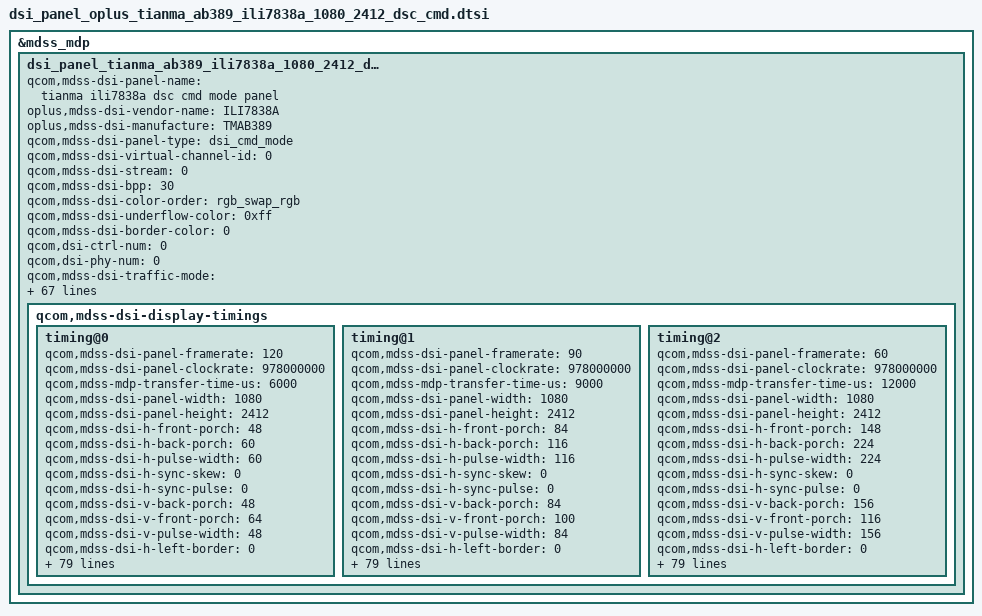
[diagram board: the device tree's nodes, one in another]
&mdss_mdp {
	dsi_panel_tianma_ab389_ili7838a_1080_2412_dsc_cmd: qcom,mdss_dsi_panel_tianma_ab389_ili7838a_1080_2412_dsc_cmd {
		qcom,mdss-dsi-panel-name = "tianma ili7838a dsc cmd mode panel";
		oplus,mdss-dsi-vendor-name = "ILI7838A";
		oplus,mdss-dsi-manufacture = "TMAB389";
		qcom,mdss-dsi-panel-type = "dsi_cmd_mode";
		qcom,mdss-dsi-virtual-channel-id = <0>;
		qcom,mdss-dsi-stream = <0>;
		qcom,mdss-dsi-bpp = <30>;
		qcom,mdss-dsi-color-order = "rgb_swap_rgb";
		qcom,mdss-dsi-underflow-color = <0xff>;
		qcom,mdss-dsi-border-color = <0>;
		qcom,dsi-ctrl-num = <0>;
		qcom,dsi-phy-num = <0>;
		qcom,mdss-dsi-traffic-mode = "non_burst_sync_event";
		qcom,mdss-dsi-lane-map = "lane_map_0123";
		qcom,mdss-dsi-bllp-eof-power-mode;
		qcom,mdss-dsi-bllp-power-mode;
		qcom,mdss-dsi-lane-0-state;
		qcom,mdss-dsi-lane-1-state;
		qcom,mdss-dsi-lane-2-state;
		qcom,mdss-dsi-lane-3-state;
		qcom,mdss-dsi-dma-trigger = "trigger_sw";
		qcom,mdss-dsi-mdp-trigger = "none";
		qcom,mdss-dsi-reset-sequence = <1 10>, <0 10>, <1 10>;

		qcom,mdss-dsi-te-pin-select = <1>;
		qcom,mdss-dsi-te-dcs-command = <1>;
		qcom,mdss-dsi-te-check-enable;
		qcom,mdss-dsi-te-using-te-pin;
		qcom,mdss-dsi-lp11-init;
		qcom,mdss-dsi-wr-mem-start = <0x2c>;
		qcom,mdss-dsi-wr-mem-continue = <0x3c>;
		qcom,mdss-dsi-panel-hdr-enabled;
		qcom,mdss-dsi-panel-hdr-color-primaries = <15635 16450 34000 16000 13250 34500 7500 3000>;
		qcom,mdss-dsi-panel-peak-brightness = <5400000>;
		qcom,mdss-dsi-panel-blackness-level = <2000>;
		qcom,mdss-pan-physical-width-dimension = <70>;
		qcom,mdss-pan-physical-height-dimension = <155>;
		qcom,esd-check-enabled;
		qcom,mdss-dsi-panel-status-check-mode = "reg_read";
		qcom,mdss-dsi-panel-status-command = [06 01 00 01 00 00 01 0A];
		qcom,mdss-dsi-panel-status-command-state = "dsi_lp_mode";
		qcom,mdss-dsi-panel-status-value = <0x9C>;
		qcom,mdss-dsi-panel-status-read-length = <1>;
		qcom,dynamic-mode-switch-enabled;
		qcom,dynamic-mode-switch-type = "dynamic-resolution-switch-immediate";
		qcom,mdss-dsi-display-timings {
			timing@0 {
				qcom,mdss-dsi-panel-framerate = <120>;
				qcom,mdss-dsi-panel-clockrate = <978000000>;
				qcom,mdss-mdp-transfer-time-us = <6000>;
				qcom,mdss-dsi-panel-width = <1080>;
				qcom,mdss-dsi-panel-height = <2412>;
				qcom,mdss-dsi-h-front-porch = <48>;
				qcom,mdss-dsi-h-back-porch = <60>;
				qcom,mdss-dsi-h-pulse-width = <60>;
				qcom,mdss-dsi-h-sync-skew = <0>;
				qcom,mdss-dsi-h-sync-pulse = <0>;
				qcom,mdss-dsi-v-back-porch = <48>;
				qcom,mdss-dsi-v-front-porch = <64>;
				qcom,mdss-dsi-v-pulse-width = <48>;
				qcom,mdss-dsi-h-left-border = <0>;
				qcom,mdss-dsi-h-right-border = <0>;
				qcom,mdss-dsi-v-top-border = <0>;
				qcom,mdss-dsi-v-bottom-border = <0>;
				qcom,mdss-dsi-panel-jitter = <0x4 0x1>;

				/* ofp config */
				oplus,ofp-need-to-separate-backlight;
				oplus,ofp-hbm-on-period = <2>;

				qcom,mdss-dsi-timing-switch-command = [
					//120HZ
					39 00 00 40 00 00 04 FF 78 38 02
					39 00 00 40 00 00 02 38 11
					39 00 00 00 00 00 04 FF 78 38 00
				];
				qcom,mdss-dsi-on-command = [
					//APL Peak Luminance ON
					39 00 00 40 00 00 04 FF 78 38 0B
					39 00 00 40 00 00 02 17 F3
					39 00 00 40 00 00 02 18 F3
					39 00 00 40 00 00 02 19 F3
					39 00 00 40 00 00 02 1A F3
					39 00 00 40 00 00 02 1B F3
					39 00 00 40 00 00 02 1C F3
					39 00 00 40 00 00 02 1D F3
					39 00 00 40 00 00 04 FF 78 38 0A
					39 00 00 40 00 00 02 37 4F
					39 00 00 40 00 00 02 38 70
					39 00 00 40 00 00 04 FF 78 38 00
					39 00 00 00 00 00 02 55 03
					//R Corner Control off
					39 00 00 40 00 00 04 FF 78 38 17
					39 00 00 00 00 00 02 20 00
					//NVM Reload
					39 00 00 40 00 00 04 FF 78 38 08
					39 00 00 00 00 00 02 45 4C
					//DSC 10Bit
					39 00 00 40 00 00 04 FF 78 38 07
					39 00 00 40 00 00 02 29 01
					39 00 00 00 00 00 64 20 00 00 00
					00 00 11 00 00 ab 30 a0 09 6c 04
					38 00 0c 02 1c 02 a3 01 9a 01 d8
					00 19 01 03 00 0a 00 0c 08 bb 0a
					5f 16 00 10 ec 07 10 20 00 06 0f
					0f 33 0e 1c 2a 38 46 54 62 69 70
					77 79 7b 7d 7e 01 c2 22 00 2a 40
					32 be 3a fc 3a fa 3a f8 3b 38 3b
					78 3b 76 4b b6 4b b6 4b f4 5b f4
					7c 34 00 00 00 00 00 00
					//Frequence Transition
					39 00 00 40 00 00 04 FF 78 38 02
					39 00 00 00 00 00 02 38 11
					//IR IP ON
					39 00 00 40 00 00 04 FF 78 38 00
					39 00 00 00 00 00 02 95 10
					//TE ON
					39 00 00 40 00 00 04 FF 78 38 00
					39 00 00 00 00 00 02 35 00
					//Dimming Setting
					39 00 00 40 00 00 02 53 20
					39 00 00 00 00 00 03 51 00 00
					//Sleep out
					05 00 00 00 78 00 01 11
					//ESD Check
					39 00 00 40 00 00 04 FF 78 38 08
					39 00 00 40 00 00 02 57 25
					39 00 00 40 00 00 04 FF 78 38 06
					39 00 00 40 0A 00 02 C6 01
					39 00 00 00 00 00 04 FF 78 38 00
					//Display on
					05 00 00 00 46 00 01 29
				];
				qcom,mdss-dsi-off-command= [
					05 00 00 40 0B 00 01 28
					05 00 00 00 79 00 01 10];
				qcom,mdss-dsi-post-on-backlight = [
					/* Display On */
					05 00 00 00 00 00 01 29
				];
				qcom,mdss-dsi-panel-info-switch-page-command = [
					/*read panel info switch page 0f*/
					39 00 00 00 00 00 04 FF 78 38 0F
				];
				qcom,mdss-dsi-default-switch-page-command = [
					/*switch default page*/
					39 00 00 00 00 00 04 FF 78 38 00
				];

				//qcom,mdss-dsi-seed-off-command = [

				//];
				//qcom,mdss-dsi-seed-3-command = [

				//];
				//qcom,mdss-dsi-seed-2-command = [

				//];
				//qcom,mdss-dsi-seed-1-command = [

				//];
				//qcom,mdss-dsi-seed-0-command = [

				//];
				qcom,mdss-dsi-hbm-enter-switch-command = [
					39 00 00 00 00 00 03 51 0D BB
				];
				qcom,mdss-dsi-hbm-exit-switch-command = [
					39 00 00 00 00 00 03 51 0D BB
				];

				qcom,mdss-dsi-hbm-on-command = [
					/* HBM Mode ON */
					39 00 00 00 00 00 03 51 0F FF
				];
				qcom,mdss-dsi-hbm-off-command = [
					/* HBM Mode OFF */
					39 00 00 00 00 00 03 51 0D BB
				];
				qcom,mdss-dsi-lp1-command = [
					/* AOD Mode ON */
					39 00 00 40 00 00 04 FF 78 38 00
					05 00 00 40 00 00 01 39
					39 00 00 40 00 00 04 FF 78 38 0C
					15 00 00 40 00 00 02 BE 01
					39 00 00 00 00 00 04 FF 78 38 00
				];
				qcom,mdss-dsi-nolp-command = [
					/* AOD Mode OFF */
					39 00 00 40 00 00 04 FF 78 38 00
					05 00 00 40 00 00 01 38
					39 00 00 00 00 00 03 51 00 00
				];
				qcom,mdss-dsi-aod-high-mode-command = [
					/* AOD High Mode, 50nit */
					39 00 00 40 00 00 04 FF 78 38 0C
					15 00 00 40 00 00 02 BE 01
					39 00 00 00 00 00 04 FF 78 38 00
				];
				qcom,mdss-dsi-aod-low-mode-command = [
					/* AOD Low Mode 10nit */
					39 00 00 40 00 00 04 FF 78 38 0C
					15 00 00 40 00 00 02 BE 00
					39 00 00 00 00 00 04 FF 78 38 00
				];

				qcom,mdss-dsi-loading-effect-1-command = [
				];
				qcom,mdss-dsi-loading-effect-2-command = [
				];
				qcom,mdss-dsi-loading-effect-off-command = [
				];

				qcom,mdss-dsi-osc-clk-mode0-command = [

				];
				qcom,mdss-dsi-osc-clk-mode1-command = [

				];
				qcom,mdss-dsi-timing-switch-command-state = "dsi_lp_mode";
				qcom,mdss-dsi-on-command-state = "dsi_lp_mode";
				qcom,mdss-dsi-off-command-state = "dsi_lp_mode";
				qcom,mdss-dsi-panel-info-switch-page-command-state = "dsi_lp_mode";
				qcom,mdss-dsi-default-switch-page-command-state = "dsi_lp_mode";
				qcom,mdss-dsi-hbm-on-command-state = "dsi_lp_mode";
				qcom,mdss-dsi-hbm-off-command-state = "dsi_lp_mode";
				qcom,mdss-dsi-lp1-command-state = "dsi_lp_mode";
				qcom,mdss-dsi-nolp-command-state = "dsi_lp_mode";
				qcom,mdss-dsi-aod-high-mode-command-state = "dsi_lp_mode";
				qcom,mdss-dsi-aod-low-mode-command-state = "dsi_lp_mode";
				qcom,mdss-dsi-loading-effect-1-command-state = "dsi_lp_mode";
				qcom,mdss-dsi-loading-effect-2-command-state = "dsi_lp_mode";
				qcom,mdss-dsi-loading-effect-off-command-state = "dsi_lp_mode";
				qcom,mdss-dsi-osc-clk-mode0-command-state = "dsi_lp_mode";
				qcom,mdss-dsi-osc-clk-mode1-command-state = "dsi_lp_mode";
				//qcom,mdss-dsi-seed-0-command-state = "dsi_lp_mode";
				//qcom,mdss-dsi-seed-1-command-state = "dsi_lp_mode";
				//qcom,mdss-dsi-seed-2-command-state = "dsi_lp_mode";
				//qcom,mdss-dsi-seed-3-command-state = "dsi_lp_mode";
				//qcom,mdss-dsi-seed-off-command-state = "dsi_lp_mode";
				qcom,compression-mode = "dsc";
				qcom,mdss-dsc-slice-height = <12>;
				qcom,mdss-dsc-slice-width = <540>;
				qcom,mdss-dsc-slice-per-pkt = <2>;
				qcom,mdss-dsc-bit-per-component = <10>;
				qcom,mdss-dsc-bit-per-pixel = <10>;
				qcom,mdss-dsc-block-prediction-enable;
				qcom,mdss-dsc-version = <0x12>;
			};
			timing@1 {
				qcom,mdss-dsi-panel-framerate = <90>;
				qcom,mdss-dsi-panel-clockrate = <978000000>;
				qcom,mdss-mdp-transfer-time-us = <9000>;
				qcom,mdss-dsi-panel-width = <1080>;
				qcom,mdss-dsi-panel-height = <2412>;
				qcom,mdss-dsi-h-front-porch = <84>;
				qcom,mdss-dsi-h-back-porch = <116>;
				qcom,mdss-dsi-h-pulse-width = <116>;
				qcom,mdss-dsi-h-sync-skew = <0>;
				qcom,mdss-dsi-h-sync-pulse = <0>;
				qcom,mdss-dsi-v-back-porch = <84>;
				qcom,mdss-dsi-v-front-porch = <100>;
				qcom,mdss-dsi-v-pulse-width = <84>;
				qcom,mdss-dsi-h-left-border = <0>;
				qcom,mdss-dsi-h-right-border = <0>;
				qcom,mdss-dsi-v-top-border = <0>;
				qcom,mdss-dsi-v-bottom-border = <0>;
				qcom,mdss-dsi-panel-jitter = <0x4 0x1>;

				/* ofp config */
				oplus,ofp-need-to-separate-backlight;
				oplus,ofp-hbm-on-period = <2>;

				qcom,mdss-dsi-timing-switch-command = [
					//90HZ
					39 00 00 40 00 00 04 FF 78 38 02
					39 00 00 40 00 00 02 38 12
					39 00 00 00 00 00 04 FF 78 38 00
				];
				qcom,mdss-dsi-on-command = [
					//APL Peak Luminance ON
					39 00 00 40 00 00 04 FF 78 38 0B
					39 00 00 40 00 00 02 17 F3
					39 00 00 40 00 00 02 18 F3
					39 00 00 40 00 00 02 19 F3
					39 00 00 40 00 00 02 1A F3
					39 00 00 40 00 00 02 1B F3
					39 00 00 40 00 00 02 1C F3
					39 00 00 40 00 00 02 1D F3
					39 00 00 40 00 00 04 FF 78 38 0A
					39 00 00 40 00 00 02 37 4F
					39 00 00 40 00 00 02 38 70
					39 00 00 40 00 00 04 FF 78 38 00
					39 00 00 00 00 00 02 55 03
					//R Corner Control off
					39 00 00 40 00 00 04 FF 78 38 17
					39 00 00 00 00 00 02 20 00
					//NVM Reload
					39 00 00 40 00 00 04 FF 78 38 08
					39 00 00 00 00 00 02 45 4C
					//DSC 10Bit
					39 00 00 40 00 00 04 FF 78 38 07
					39 00 00 40 00 00 02 29 01
					39 00 00 00 00 00 64 20 00 00 00
					00 00 11 00 00 ab 30 a0 09 6c 04
					38 00 0c 02 1c 02 a3 01 9a 01 d8
					00 19 01 03 00 0a 00 0c 08 bb 0a
					5f 16 00 10 ec 07 10 20 00 06 0f
					0f 33 0e 1c 2a 38 46 54 62 69 70
					77 79 7b 7d 7e 01 c2 22 00 2a 40
					32 be 3a fc 3a fa 3a f8 3b 38 3b
					78 3b 76 4b b6 4b b6 4b f4 5b f4
					7c 34 00 00 00 00 00 00
					//Frequence Transition
					39 00 00 40 00 00 04 FF 78 38 02
					39 00 00 00 00 00 02 38 12
					//IR IP ON
					39 00 00 40 00 00 04 FF 78 38 00
					39 00 00 00 00 00 02 95 10
					//TE ON
					39 00 00 40 00 00 04 FF 78 38 00
					39 00 00 00 00 00 02 35 00
					//Dimming Setting
					39 00 00 40 00 00 02 53 20
					39 00 00 00 00 00 03 51 00 00
					//Sleep out
					05 00 00 00 78 00 01 11
					//ESD Check
					39 00 00 40 00 00 04 FF 78 38 08
					39 00 00 40 00 00 02 57 25
					39 00 00 40 00 00 04 FF 78 38 06
					39 00 00 40 0A 00 02 C6 01
					39 00 00 00 00 00 04 FF 78 38 00
					//Display on
					05 00 00 00 46 00 01 29
				];
				qcom,mdss-dsi-off-command= [
					05 00 00 40 0B 00 01 28
					05 00 00 00 79 00 01 10];
				qcom,mdss-dsi-post-on-backlight = [
					/* Display On */
					05 00 00 00 00 00 01 29
				];
				qcom,mdss-dsi-panel-info-switch-page-command = [
					/*read panel info switch page 0f*/
					39 00 00 00 00 00 04 FF 78 38 0F
				];
				qcom,mdss-dsi-default-switch-page-command = [
					/*switch default page*/
					39 00 00 00 00 00 04 FF 78 38 00
				];

				qcom,mdss-dsi-hbm-enter-switch-command = [
					39 00 00 00 00 00 03 51 0D BB
				];
				qcom,mdss-dsi-hbm-exit-switch-command = [
					39 00 00 00 00 00 03 51 0D BB
				];

				qcom,mdss-dsi-hbm-on-command = [
					/* HBM Mode ON */
					39 00 00 00 00 00 03 51 0F FF
				];
				qcom,mdss-dsi-hbm-off-command = [
					/* HBM Mode OFF */
					39 00 00 00 00 00 03 51 0D BB
				];
				qcom,mdss-dsi-lp1-command = [
					/* AOD Mode ON */
					39 00 00 40 00 00 04 FF 78 38 00
					05 00 00 40 00 00 01 39
					39 00 00 40 00 00 04 FF 78 38 0C
					15 00 00 40 00 00 02 BE 01
					39 00 00 00 00 00 04 FF 78 38 00
				];
				qcom,mdss-dsi-nolp-command = [
					/* AOD Mode OFF */
					39 00 00 40 00 00 04 FF 78 38 00
					05 00 00 40 00 00 01 38
					39 00 00 00 00 00 03 51 00 00
				];
				qcom,mdss-dsi-aod-high-mode-command = [
					/* AOD High Mode, 50nit */
					39 00 00 40 00 00 04 FF 78 38 0C
					15 00 00 40 00 00 02 BE 01
					39 00 00 00 00 00 04 FF 78 38 00
				];
				qcom,mdss-dsi-aod-low-mode-command = [
					/* AOD Low Mode 10nit */
					39 00 00 40 00 00 04 FF 78 38 0C
					15 00 00 40 00 00 02 BE 00
					39 00 00 00 00 00 04 FF 78 38 00
				];

				qcom,mdss-dsi-loading-effect-1-command = [
				];
				qcom,mdss-dsi-loading-effect-2-command = [
				];
				qcom,mdss-dsi-loading-effect-off-command = [
				];

				qcom,mdss-dsi-osc-clk-mode0-command = [

				];
				qcom,mdss-dsi-osc-clk-mode1-command = [

				];
				qcom,mdss-dsi-timing-switch-command-state = "dsi_lp_mode";
				qcom,mdss-dsi-on-command-state = "dsi_lp_mode";
				qcom,mdss-dsi-off-command-state = "dsi_lp_mode";
				qcom,mdss-dsi-panel-info-switch-page-command-state = "dsi_lp_mode";
				qcom,mdss-dsi-default-switch-page-command-state = "dsi_lp_mode";
				qcom,mdss-dsi-hbm-on-command-state = "dsi_lp_mode";
				qcom,mdss-dsi-hbm-off-command-state = "dsi_lp_mode";
				qcom,mdss-dsi-lp1-command-state = "dsi_lp_mode";
				qcom,mdss-dsi-nolp-command-state = "dsi_lp_mode";
				qcom,mdss-dsi-aod-high-mode-command-state = "dsi_lp_mode";
				qcom,mdss-dsi-aod-low-mode-command-state = "dsi_lp_mode";
				qcom,mdss-dsi-loading-effect-1-command-state = "dsi_lp_mode";
				qcom,mdss-dsi-loading-effect-2-command-state = "dsi_lp_mode";
				qcom,mdss-dsi-loading-effect-off-command-state = "dsi_lp_mode";
				qcom,mdss-dsi-osc-clk-mode0-command-state = "dsi_lp_mode";
				qcom,mdss-dsi-osc-clk-mode1-command-state = "dsi_lp_mode";
				qcom,compression-mode = "dsc";
				qcom,mdss-dsc-slice-height = <12>;
				qcom,mdss-dsc-slice-width = <540>;
				qcom,mdss-dsc-slice-per-pkt = <2>;
				qcom,mdss-dsc-bit-per-component = <10>;
				qcom,mdss-dsc-bit-per-pixel = <10>;
				qcom,mdss-dsc-block-prediction-enable;
				qcom,mdss-dsc-version = <0x12>;
			};
			timing@2 {
				qcom,mdss-dsi-panel-framerate = <60>;
				qcom,mdss-dsi-panel-clockrate = <978000000>;
				qcom,mdss-mdp-transfer-time-us = <12000>;
				qcom,mdss-dsi-panel-width = <1080>;
				qcom,mdss-dsi-panel-height = <2412>;
				qcom,mdss-dsi-h-front-porch = <148>;
				qcom,mdss-dsi-h-back-porch = <224>;
				qcom,mdss-dsi-h-pulse-width = <224>;
				qcom,mdss-dsi-h-sync-skew = <0>;
				qcom,mdss-dsi-h-sync-pulse = <0>;
				qcom,mdss-dsi-v-back-porch = <156>;
				qcom,mdss-dsi-v-front-porch = <116>;
				qcom,mdss-dsi-v-pulse-width = <156>;
				qcom,mdss-dsi-h-left-border = <0>;
				qcom,mdss-dsi-h-right-border = <0>;
				qcom,mdss-dsi-v-top-border = <0>;
				qcom,mdss-dsi-v-bottom-border = <0>;
				qcom,mdss-dsi-panel-jitter = <0x4 0x1>;

				/* ofp config */
				oplus,ofp-need-to-separate-backlight;
				oplus,ofp-hbm-on-period = <2>;

				qcom,mdss-dsi-timing-switch-command = [
					//60HZ
					39 00 00 40 00 00 04 FF 78 38 02
					39 00 00 40 00 00 02 38 13
					39 00 00 00 00 00 04 FF 78 38 00
				];
				qcom,mdss-dsi-on-command = [
					//APL Peak Luminance ON
					39 00 00 40 00 00 04 FF 78 38 0B
					39 00 00 40 00 00 02 17 F3
					39 00 00 40 00 00 02 18 F3
					39 00 00 40 00 00 02 19 F3
					39 00 00 40 00 00 02 1A F3
					39 00 00 40 00 00 02 1B F3
					39 00 00 40 00 00 02 1C F3
					39 00 00 40 00 00 02 1D F3
					39 00 00 40 00 00 04 FF 78 38 0A
					39 00 00 40 00 00 02 37 4F
					39 00 00 40 00 00 02 38 70
					39 00 00 40 00 00 04 FF 78 38 00
					39 00 00 00 00 00 02 55 03
					//R Corner Control off
					39 00 00 40 00 00 04 FF 78 38 17
					39 00 00 00 00 00 02 20 00
					//NVM Reload
					39 00 00 40 00 00 04 FF 78 38 08
					39 00 00 00 00 00 02 45 4C
					//DSC 10Bit
					39 00 00 40 00 00 04 FF 78 38 07
					39 00 00 40 00 00 02 29 01
					39 00 00 00 00 00 64 20 00 00 00
					00 00 11 00 00 ab 30 a0 09 6c 04
					38 00 0c 02 1c 02 a3 01 9a 01 d8
					00 19 01 03 00 0a 00 0c 08 bb 0a
					5f 16 00 10 ec 07 10 20 00 06 0f
					0f 33 0e 1c 2a 38 46 54 62 69 70
					77 79 7b 7d 7e 01 c2 22 00 2a 40
					32 be 3a fc 3a fa 3a f8 3b 38 3b
					78 3b 76 4b b6 4b b6 4b f4 5b f4
					7c 34 00 00 00 00 00 00
					//Frequence Transition
					39 00 00 40 00 00 04 FF 78 38 02
					39 00 00 00 00 00 02 38 13
					//IR IP ON
					39 00 00 40 00 00 04 FF 78 38 00
					39 00 00 00 00 00 02 95 10
					//TE ON
					39 00 00 40 00 00 04 FF 78 38 00
					39 00 00 00 00 00 02 35 00
					//Dimming Setting
					39 00 00 40 00 00 02 53 20
					39 00 00 00 00 00 03 51 00 00
					//Sleep out
					05 00 00 00 78 00 01 11
					//ESD Check
					39 00 00 40 00 00 04 FF 78 38 08
					39 00 00 40 00 00 02 57 25
					39 00 00 40 00 00 04 FF 78 38 06
					39 00 00 40 0A 00 02 C6 01
					39 00 00 00 00 00 04 FF 78 38 00
					//Display on
					05 00 00 00 46 00 01 29
				];
				qcom,mdss-dsi-off-command= [
					05 00 00 40 0B 00 01 28
					05 00 00 00 79 00 01 10];
				qcom,mdss-dsi-post-on-backlight = [
					/* Display On */
					05 00 00 00 00 00 01 29
				];
				qcom,mdss-dsi-panel-info-switch-page-command = [
					/*read panel info switch page 0f*/
					39 00 00 00 00 00 04 FF 78 38 0F
				];
				qcom,mdss-dsi-default-switch-page-command = [
					/*switch default page*/
					39 00 00 00 00 00 04 FF 78 38 00
				];

				//qcom,mdss-dsi-seed-off-command = [

				//];
				//qcom,mdss-dsi-seed-3-command = [

				//];
				//qcom,mdss-dsi-seed-2-command = [

				//];
				//qcom,mdss-dsi-seed-1-command = [

				//];
				//qcom,mdss-dsi-seed-0-command = [

				//];
				qcom,mdss-dsi-hbm-enter-switch-command = [
					39 00 00 00 00 00 03 51 0D BB
				];
				qcom,mdss-dsi-hbm-exit-switch-command = [
					39 00 00 00 00 00 03 51 0D BB
				];

				qcom,mdss-dsi-hbm-on-command = [
					/* HBM Mode ON */
					39 00 00 00 00 00 03 51 0F FF
				];
				qcom,mdss-dsi-hbm-off-command = [
					/* HBM Mode OFF */
					39 00 00 00 00 00 03 51 0D BB
				];
				qcom,mdss-dsi-lp1-command = [
					/* AOD Mode ON */
					39 00 00 40 00 00 04 FF 78 38 00
					05 00 00 40 00 00 01 39
					39 00 00 40 00 00 04 FF 78 38 0C
					15 00 00 40 00 00 02 BE 01
					39 00 00 00 00 00 04 FF 78 38 00
				];
				qcom,mdss-dsi-nolp-command = [
					/* AOD Mode OFF */
					39 00 00 40 00 00 04 FF 78 38 00
					05 00 00 40 00 00 01 38
					39 00 00 00 00 00 03 51 00 00
				];
				qcom,mdss-dsi-aod-high-mode-command = [
					/* AOD High Mode, 50nit */
					39 00 00 40 00 00 04 FF 78 38 0C
					15 00 00 40 00 00 02 BE 01
					39 00 00 00 00 00 04 FF 78 38 00
				];
				qcom,mdss-dsi-aod-low-mode-command = [
					/* AOD Low Mode 10nit */
					39 00 00 40 00 00 04 FF 78 38 0C
					15 00 00 40 00 00 02 BE 00
					39 00 00 00 00 00 04 FF 78 38 00
				];

				qcom,mdss-dsi-loading-effect-1-command = [
				];
				qcom,mdss-dsi-loading-effect-2-command = [
				];
				qcom,mdss-dsi-loading-effect-off-command = [
				];

				qcom,mdss-dsi-osc-clk-mode0-command = [

				];
				qcom,mdss-dsi-osc-clk-mode1-command = [

				];

				qcom,mdss-dsi-timing-switch-command-state = "dsi_lp_mode";
				qcom,mdss-dsi-on-command-state = "dsi_lp_mode";
				qcom,mdss-dsi-off-command-state = "dsi_lp_mode";
				qcom,mdss-dsi-panel-info-switch-page-command-state = "dsi_lp_mode";
				qcom,mdss-dsi-default-switch-page-command-state = "dsi_lp_mode";
				qcom,mdss-dsi-hbm-on-command-state = "dsi_lp_mode";
				qcom,mdss-dsi-hbm-off-command-state = "dsi_lp_mode";
				qcom,mdss-dsi-lp1-command-state = "dsi_lp_mode";
				qcom,mdss-dsi-nolp-command-state = "dsi_lp_mode";
				qcom,mdss-dsi-aod-high-mode-command-state = "dsi_lp_mode";
				qcom,mdss-dsi-aod-low-mode-command-state = "dsi_lp_mode";
				qcom,mdss-dsi-loading-effect-1-command-state = "dsi_lp_mode";
				qcom,mdss-dsi-loading-effect-2-command-state = "dsi_lp_mode";
				qcom,mdss-dsi-loading-effect-off-command-state = "dsi_lp_mode";
				qcom,mdss-dsi-osc-clk-mode0-command-state = "dsi_lp_mode";
				qcom,mdss-dsi-osc-clk-mode1-command-state = "dsi_lp_mode";
				//qcom,mdss-dsi-seed-0-command-state = "dsi_lp_mode";
				//qcom,mdss-dsi-seed-1-command-state = "dsi_lp_mode";
				//qcom,mdss-dsi-seed-2-command-state = "dsi_lp_mode";
				//qcom,mdss-dsi-seed-3-command-state = "dsi_lp_mode";
				//qcom,mdss-dsi-seed-off-command-state = "dsi_lp_mode";
				qcom,compression-mode = "dsc";
				qcom,mdss-dsc-slice-height = <12>;
				qcom,mdss-dsc-slice-width = <540>;
				qcom,mdss-dsc-slice-per-pkt = <2>;
				qcom,mdss-dsc-bit-per-component = <10>;
				qcom,mdss-dsc-bit-per-pixel = <10>;
				qcom,mdss-dsc-block-prediction-enable;
				qcom,mdss-dsc-version = <0x12>;
			};
		};
	};
};



&dsi_panel_tianma_ab389_ili7838a_1080_2412_dsc_cmd {
	qcom,panel-supply-entries = <&dsi_panel_oplus_optimization_pwr_supply_lvzhou>;
	qcom,mdss-dsi-panel-controller = <&mdss_dsi0>;
	qcom,mdss-dsi-bl-pmic-control-type = "bl_ctrl_dcs";
	qcom,mdss-dsi-bl-inverted-dbv;
	qcom,mdss-dsi-bl-min-level = <1>;
	qcom,mdss-dsi-bl-max-level = <4095>;
	qcom,mdss-brightness-max-level = <4095>;
	oplus,dsi-bl-normal-max-level = <3515>;
	oplus,dsi-brightness-normal-max-level = <3515>;
	oplus,dsi-brightness-default-level = <1638>;
	qcom,platform-te-gpio = <&tlmm 86 0>;
	qcom,platform-reset-gpio = <&tlmm 3 0>;
	qcom,ulps-enabled;
	qcom,dsi-select-clocks = "pll_byte_clk0", "pll_dsi_clk0";
	/* ofp config */
	oplus,ofp-fp-type = <0x08>;
	/* serial num config */
	oplus,dsi-serial-number-enabled;
	oplus,dsi-serial-number-index= <0>;
	oplus,dsi-serial-number-switch-page;
	oplus,dsi-serial-number-multi-reg;
	oplus,dsi-serial-number-multi-regs = [00 01 02 03 04 05 06];

	qcom,mdss-dsi-display-timings {
		timing@0 {
				qcom,mdss-dsi-panel-phy-timings = [00 21 08 08 19 22 09 08 09 02 04 00 1C 0D];
				qcom,display-topology = <1 1 1>,<2 2 1>;
				qcom,default-topology-index = <0>;
		};
		timing@1 {
				qcom,mdss-dsi-panel-phy-timings = [00 21 08 08 19 22 09 08 09 02 04 00 1C 0D];
				qcom,display-topology = <1 1 1>,<2 2 1>;
				qcom,default-topology-index = <0>;
		};
		timing@2 {
				qcom,mdss-dsi-panel-phy-timings = [00 21 08 08 19 22 09 08 09 02 04 00 1C 0D];
				qcom,display-topology = <1 1 1>,<2 2 1>;
				qcom,default-topology-index = <0>;
		};
	};
};

&dsi_panel_tianma_ab389_ili7838a_1080_2412_dsc_cmd {
	qcom,panel_voltage_vddi_name = "vddio";
	qcom,panel_voltage_vddi = <0 1800000 1850000 1950000>;
	qcom,panel_voltage_vddr_name = "vddio";
	qcom,panel_voltage_vddr = <1 1800000 1850000 1950000>;
};
